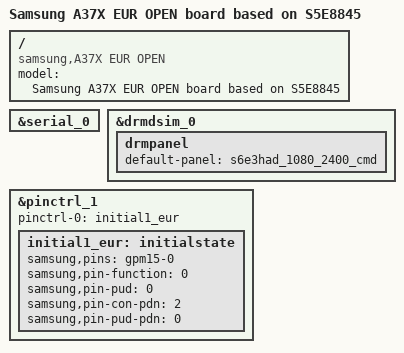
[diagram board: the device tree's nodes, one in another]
/*
 * SAMSUNG S5E8845 board device tree source
 *
 * Copyright (c) 2023 Samsung Electronics Co., Ltd.
 *		http://www.samsung.com
 *
 * This program is free software; you can redistribute it and/or modify
 * it under the terms of the GNU General Public License version 2 as
 * published by the Free Software Foundation.
 */

#include "s5e8845-a37x_common.dtsi"
#include "s5e8845-a37x.pm.00.dtsi"
//#include "panel/samsung-emulation-video-panel.dtsi"
//#include "../../exynos/board/panel/samsung-s6e3had-1080-2400-command-panel.dtsi"
#include "camera/s5e8845-a37x-camera_01.dtsi"

/ {
	compatible = "samsung,A37X EUR OPEN", "samsung,S5E8845";

	fragment@model {
		target-path = "/";
		__overlay__ {
			#address-cells = <2>;
			#size-cells = <1>;

			model = "Samsung A37X EUR OPEN board based on S5E8845";
		}; /* end of __overlay__ */
	}; /* end of fragment */
}; /* end of root */

&serial_0 {
	status = "okay";
};

&drmdsim_0 {
        drmpanel {
                default-panel = "s6e3had_1080_2400_cmd";
        };
};

&pinctrl_1 {
	pinctrl-names = "default";
	pinctrl-0 = <&initial1_eur>;
	initial1_eur: initialstate {
		samsung,pins = "gpm15-0";
		samsung,pin-function = <0>;
		samsung,pin-pud = <0>;
		samsung,pin-con-pdn = <2>;
		samsung,pin-pud-pdn = <0>;
	};
};
